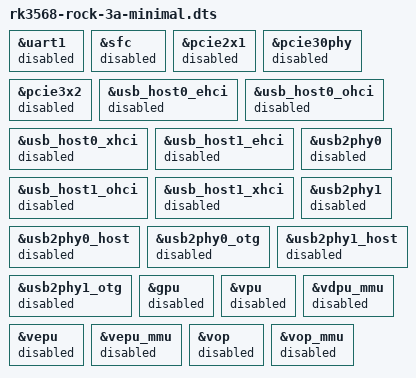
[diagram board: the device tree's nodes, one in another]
#include "rk3568-rock-3a.dts"

&uart1 {
	status = "disabled";
	/delete-node/ bluetooth;
};

&sfc {
	status = "disabled";
};

&pcie2x1 {
	status = "disabled";
};

&pcie30phy {
	status = "disabled";
};

&pcie3x2 {
	status = "disabled";
};

&usb_host0_ehci {
	status = "disabled";
};

&usb_host0_ohci {
	status = "disabled";
};

&usb_host0_xhci {
	status = "disabled";
};

&usb_host1_ehci {
	status = "disabled";
};

&usb_host1_ohci {
	status = "disabled";
};

&usb_host1_xhci {
	status = "disabled";
};

&usb2phy0 {
	status = "disabled";
};

&usb2phy0_host {
	status = "disabled";
};

&usb2phy0_otg {
	status = "disabled";
};

&usb2phy1 {
	status = "disabled";
};

&usb2phy1_host {
	status = "disabled";
};

&usb2phy1_otg {
	status = "disabled";
};

&gpu {
	status = "disabled";
};

&vpu {
	status = "disabled";
};

&vdpu_mmu {
	status = "disabled";
};

&vepu {
	status = "disabled";
};

&vepu_mmu {
	status = "disabled";
};

&vop {
	status = "disabled";
};

&vop_mmu {
	status = "disabled";
};
